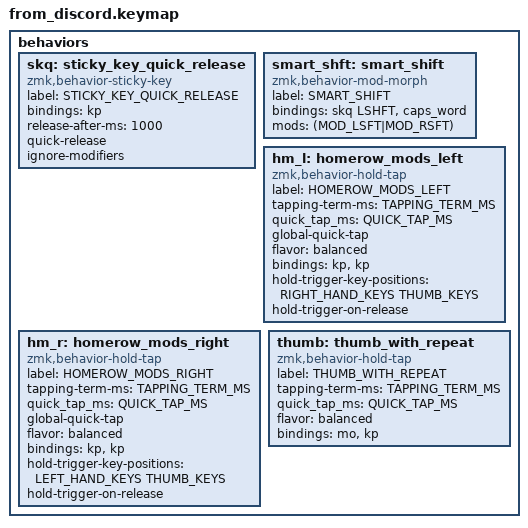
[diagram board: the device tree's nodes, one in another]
behaviors {
    #define LEFT_HAND_KEYS      \
          0  1  2  3  4         \
         10 11 12 13 14 15      \
         22 23 24 25 26 27      \
         34 35 36 37 38 39      \
         46 47 48 49 50 51      \
         64 65 66 67 68
    #define                              RIGHT_HAND_KEYS \
                                           5  6  7  8  9 \
                                       16 17 18 19 20 21 \
                                       28 29 30 31 32 33 \
                                       40 41 42 43 44 45 \
                                       58 59 60 61 62 63 \
                                          75 76 77 78 79
    #define THUMB_KEYS          \
                        69 52       57 74                \
                         70 53     56 73                 \
                          71 54   55 72

    #define QUICK_TAP_MS 175
    #define TAPPING_TERM_MS 280

    // We cannot override global behaviors yet (?), so make a sticky key behavior.
    skq: sticky_key_quick_release {
        compatible = "zmk,behavior-sticky-key";
        label = "STICKY_KEY_QUICK_RELEASE";
        #binding-cells = <1>;
        bindings = <&kp>;
        release-after-ms = <1000>;
        quick-release;
        ignore-modifiers;
    };

    smart_shft: smart_shift {
        compatible = "zmk,behavior-mod-morph";
        label = "SMART_SHIFT";
        #binding-cells = <0>;
        bindings = <&skq LSHFT>, <&caps_word>;
        mods = <(MOD_LSFT|MOD_RSFT)>;
    };

    hm_l: homerow_mods_left {
        compatible = "zmk,behavior-hold-tap";
        label = "HOMEROW_MODS_LEFT";
        #binding-cells = <2>;
        tapping-term-ms = <TAPPING_TERM_MS>;
        quick_tap_ms = <QUICK_TAP_MS>;
        global-quick-tap;
        flavor = "balanced";
        bindings = <&kp>, <&kp>;
        hold-trigger-key-positions = <RIGHT_HAND_KEYS THUMB_KEYS>;
        hold-trigger-on-release;
    };

    hm_r: homerow_mods_right {
        compatible = "zmk,behavior-hold-tap";
        label = "HOMEROW_MODS_RIGHT";
        #binding-cells = <2>;
        tapping-term-ms = <TAPPING_TERM_MS>;
        quick_tap_ms = <QUICK_TAP_MS>;
        global-quick-tap;
        flavor = "balanced";
        bindings = <&kp>, <&kp>;
        hold-trigger-key-positions = <LEFT_HAND_KEYS THUMB_KEYS>;
        hold-trigger-on-release;
    };

    thumb: thumb_with_repeat {
        compatible = "zmk,behavior-hold-tap";
        label = "THUMB_WITH_REPEAT";
        #binding-cells = <2>;
        tapping-term-ms = <TAPPING_TERM_MS>;
        quick_tap_ms = <QUICK_TAP_MS>;
        // global-quick-tap;
        flavor = "balanced";
        bindings = <&mo>, <&kp>;
    };
};
